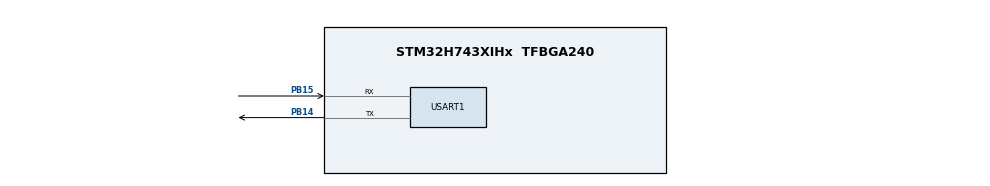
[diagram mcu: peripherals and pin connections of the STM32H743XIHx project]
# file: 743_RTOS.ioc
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FREERTOS.BinarySemaphores01=mySemaphore,Dynamic,NULL
FREERTOS.Events01=SendFlag,Dynamic,NULL
FREERTOS.Tasks01=defaultTask,24,128,StartDefaultTask,Default,NULL,Dynamic,NULL,NULL;myBuyTask,8,128,BuyTask,Default,(void *)mySemaphoreHandle,Dynamic,NULL,NULL;mySellTask,8,128,SellTask,Default,(void *)mySemaphoreHandle,Dynamic,NULL,NULL;mySendEvent,8,128,SendEvent,Default,NULL,Dynamic,NULL,NULL;myRcvEvent,8,128,RcvEvent,Default,NULL,Dynamic,NULL,NULL;myPoolTask01,8,128,PoolTask01,Default,(void *)properties,Dynamic,NULL,NULL;myPoolTask02,8,128,PoolTask02,Default,(void *)properties,Dynamic,NULL,NULL;myMailSendTask,8,128,MailSendTask,Default,NULL,Dynamic,NULL,NULL;myMailRcvTask,8,128,MailRcvTask,Default,NULL,Dynamic,NULL,NULL
Mcu.Family=STM32H7
Mcu.Name=STM32H743XIHx
Mcu.Package=TFBGA240
NVIC.PriorityGroup=NVIC_PRIORITYGROUP_4
NVIC.TIM7_IRQn=true\:15\:0\:false\:false\:true\:false\:false\:true\:true
NVIC.TimeBase=TIM7_IRQn
NVIC.TimeBaseIP=TIM7
NVIC.USART1_IRQn=true\:5\:0\:false\:false\:true\:true\:true\:true\:true
PB14.Mode=Asynchronous
PB14.Signal=USART1_TX
PB15.Mode=Asynchronous
PB15.Signal=USART1_RX
PH0-OSC_IN\ (PH0).Mode=HSE-External-Oscillator
PH0-OSC_IN\ (PH0).Signal=RCC_OSC_IN
PH1-OSC_OUT\ (PH1).Mode=HSE-External-Oscillator
PH1-OSC_OUT\ (PH1).Signal=RCC_OSC_OUT
ProjectManager.HeapSize=0x200
ProjectManager.StackSize=0x400
ProjectManager.TargetToolchain=EWARM V8.50
RCC.ADCFreq_Value=50390625
RCC.APB1Freq_Value=100000000
RCC.APB2Freq_Value=100000000
RCC.APB3Freq_Value=100000000
RCC.APB4Freq_Value=100000000
RCC.CortexFreq_Value=200000000
RCC.D1PPRE=RCC_APB3_DIV2
RCC.D2PPRE1=RCC_APB1_DIV2
RCC.D2PPRE2=RCC_APB2_DIV2
RCC.D3PPRE=RCC_APB4_DIV2
RCC.DIVM1=25
RCC.DIVN1=400
RCC.HCLKFreq_Value=200000000
RCC.PLLSourceVirtual=RCC_PLLSOURCE_HSE
RCC.PWR_Regulator_Voltage_Scale=PWR_REGULATOR_VOLTAGE_SCALE1
RCC.SYSCLKFreq_VALUE=200000000
RCC.SYSCLKSource=RCC_SYSCLKSOURCE_PLLCLK
RCC.USBFreq_Value=200000000
USART1.VirtualMode-Asynchronous=VM_ASYNC
VP_FREERTOS_VS_CMSIS_V2.Mode=CMSIS_V2
VP_SYS_VS_tim7.Mode=TIM7
board=custom

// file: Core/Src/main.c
/* USER CODE BEGIN Header */
/**
******************************************************************************
* @file           : main.c
* @brief          : Main program body
******************************************************************************
* @attention
*
* Copyright (c) 2023 STMicroelectronics.
* All rights reserved.
*
* This software is licensed under terms that can be found in the LICENSE file
* in the root directory of this software component.
* If no LICENSE file comes with this software, it is provided AS-IS.
*
******************************************************************************
*/
/* USER CODE END Header */
#include "main.h"
#include "cmsis_os.h"

/* USER CODE BEGIN Includes */
#include <stdio.h>
#include <string.h>
/* USER CODE END Includes */

/* USER CODE BEGIN PTD */
typedef struct {
    uint32_t len;
    uint32_t wid;
    uint32_t hei;
    uint32_t wei;
} properties_t;

typedef struct {
    double vol;
    double amp;
    double res;
} msg_t;
/* USER CODE END PTD */

UART_HandleTypeDef huart1;

/* Definitions for defaultTask */
osThreadId_t defaultTaskHandle;
const osThreadAttr_t defaultTask_attributes = {
    .name = "defaultTask",
    .stack_size = 128 * 4,
    .priority = (osPriority_t) osPriorityNormal,
};
/* Definitions for myBuyTask */
osThreadId_t myBuyTaskHandle;
const osThreadAttr_t myBuyTask_attributes = {
    .name = "myBuyTask",
    .stack_size = 128 * 4,
    .priority = (osPriority_t) osPriorityLow,
};
/* Definitions for mySellTask */
osThreadId_t mySellTaskHandle;
const osThreadAttr_t mySellTask_attributes = {
    .name = "mySellTask",
    .stack_size = 128 * 4,
    .priority = (osPriority_t) osPriorityLow,
};
/* Definitions for mySendEvent */
osThreadId_t mySendEventHandle;
const osThreadAttr_t mySendEvent_attributes = {
    .name = "mySendEvent",
    .stack_size = 128 * 4,
    .priority = (osPriority_t) osPriorityLow,
};
/* Definitions for myRcvEvent */
osThreadId_t myRcvEventHandle;
const osThreadAttr_t myRcvEvent_attributes = {
    .name = "myRcvEvent",
    .stack_size = 128 * 4,
    .priority = (osPriority_t) osPriorityLow,
};
/* Definitions for myPoolTask01 */
osThreadId_t myPoolTask01Handle;
const osThreadAttr_t myPoolTask01_attributes = {
    .name = "myPoolTask01",
    .stack_size = 128 * 4,
    .priority = (osPriority_t) osPriorityLow,
};
/* Definitions for myPoolTask02 */
osThreadId_t myPoolTask02Handle;
const osThreadAttr_t myPoolTask02_attributes = {
    .name = "myPoolTask02",
    .stack_size = 128 * 4,
    .priority = (osPriority_t) osPriorityLow,
};
/* Definitions for myMailSendTask */
osThreadId_t myMailSendTaskHandle;
const osThreadAttr_t myMailSendTask_attributes = {
    .name = "myMailSendTask",
    .stack_size = 128 * 4,
    .priority = (osPriority_t) osPriorityLow,
};
/* Definitions for myMailRcvTask */
osThreadId_t myMailRcvTaskHandle;
const osThreadAttr_t myMailRcvTask_attributes = {
    .name = "myMailRcvTask",
    .stack_size = 128 * 4,
    .priority = (osPriority_t) osPriorityLow,
};
/* Definitions for mySemaphore */
osSemaphoreId_t mySemaphoreHandle;
const osSemaphoreAttr_t mySemaphore_attributes = {
    .name = "mySemaphore"
};
/* Definitions for SendFlag */
osEventFlagsId_t SendFlagHandle;
const osEventFlagsAttr_t SendFlag_attributes = {
    .name = "SendFlag"
};
/* USER CODE BEGIN PV */
uint8_t g_iUartRx;
int g_iBuyFlag;
int g_iTicket;
int g_iSendFlag;

properties_t  *properties;
osMemoryPoolId_t poolHandle;

osMessageQueueId_t msgHandle;

/* USER CODE END PV */

void SystemClock_Config(void);
static void MX_GPIO_Init(void);
static void MX_USART1_UART_Init(void);
void StartDefaultTask(void *argument);
void BuyTask(void *argument);
void SellTask(void *argument);
void SendEvent(void *argument);
void RcvEvent(void *argument);
void PoolTask01(void *argument);
void PoolTask02(void *argument);
void MailSendTask(void *argument);
void MailRcvTask(void *argument);

int main(void)
{

    /* MCU Configuration--------------------------------------------------------*/

    /* Reset of all peripherals, Initializes the Flash interface and the Systick. */
    HAL_Init();

    /* Configure the system clock */
    SystemClock_Config();

    /* Initialize all configured peripherals */
    MX_GPIO_Init();
    MX_USART1_UART_Init();
    /* USER CODE BEGIN 2 */
    g_iBuyFlag = 0;
    g_iSendFlag = 0;
    g_iTicket = 100000;
    char buf[32];
    sprintf(buf, "USART Test\r\n");
    HAL_UART_Transmit(&huart1, (uint8_t*)buf, strlen(buf), 100);
    HAL_UART_Receive_IT(&huart1, &g_iUartRx, sizeof(g_iUartRx));

    poolHandle = osMemoryPoolNew(16, sizeof(properties_t), NULL);

    /* USER CODE END 2 */

    /* Init scheduler */
    osKernelInitialize();

    /* Create the semaphores(s) */
    /* creation of mySemaphore */
    mySemaphoreHandle = osSemaphoreNew(1, 1, &mySemaphore_attributes);

    /* USER CODE BEGIN RTOS_QUEUES */
    /* add queues, ... */
    msgHandle = osMessageQueueNew(16, sizeof(msg_t), NULL);
    /* USER CODE END RTOS_QUEUES */

    /* Create the thread(s) */
    /* creation of defaultTask */
    defaultTaskHandle = osThreadNew(StartDefaultTask, NULL, &defaultTask_attributes);

    /* creation of myBuyTask */
    myBuyTaskHandle = osThreadNew(BuyTask, (void *)mySemaphoreHandle, &myBuyTask_attributes);

    /* creation of mySellTask */
    mySellTaskHandle = osThreadNew(SellTask, (void *)mySemaphoreHandle, &mySellTask_attributes);

    /* creation of mySendEvent */
    mySendEventHandle = osThreadNew(SendEvent, NULL, &mySendEvent_attributes);

    /* creation of myRcvEvent */
    myRcvEventHandle = osThreadNew(RcvEvent, NULL, &myRcvEvent_attributes);

    /* creation of myPoolTask01 */
    myPoolTask01Handle = osThreadNew(PoolTask01, (void *)properties, &myPoolTask01_attributes);

    /* creation of myPoolTask02 */
    myPoolTask02Handle = osThreadNew(PoolTask02, (void *)properties, &myPoolTask02_attributes);

    /* creation of myMailSendTask */
    myMailSendTaskHandle = osThreadNew(MailSendTask, NULL, &myMailSendTask_attributes);

    /* creation of myMailRcvTask */
    myMailRcvTaskHandle = osThreadNew(MailRcvTask, NULL, &myMailRcvTask_attributes);

    /* Create the event(s) */
    /* creation of SendFlag */
    SendFlagHandle = osEventFlagsNew(&SendFlag_attributes);

    /* Start scheduler */
    osKernelStart();
    /* We should never get here as control is now taken by the scheduler */
    /* Infinite loop */
    while (1)
    {

    }
}

void SystemClock_Config(void)
{
    RCC_OscInitTypeDef RCC_OscInitStruct = {0};
    RCC_ClkInitTypeDef RCC_ClkInitStruct = {0};

    /** Supply configuration update enable
    */
    HAL_PWREx_ConfigSupply(PWR_LDO_SUPPLY);

    /** Configure the main internal regulator output voltage
    */
    __HAL_PWR_VOLTAGESCALING_CONFIG(PWR_REGULATOR_VOLTAGE_SCALE1);

    while(!__HAL_PWR_GET_FLAG(PWR_FLAG_VOSRDY)) {}

    /** Initializes the RCC Oscillators according to the specified parameters
    * in the RCC_OscInitTypeDef structure.
    */
    RCC_OscInitStruct.OscillatorType = RCC_OSCILLATORTYPE_HSE;
    RCC_OscInitStruct.HSEState = RCC_HSE_ON;
    RCC_OscInitStruct.PLL.PLLState = RCC_PLL_ON;
    RCC_OscInitStruct.PLL.PLLSource = RCC_PLLSOURCE_HSE;
    RCC_OscInitStruct.PLL.PLLM = 25;
    RCC_OscInitStruct.PLL.PLLN = 400;
    RCC_OscInitStruct.PLL.PLLP = 2;
    RCC_OscInitStruct.PLL.PLLQ = 2;
    RCC_OscInitStruct.PLL.PLLR = 2;
    RCC_OscInitStruct.PLL.PLLRGE = RCC_PLL1VCIRANGE_0;
    RCC_OscInitStruct.PLL.PLLVCOSEL = RCC_PLL1VCOWIDE;
    RCC_OscInitStruct.PLL.PLLFRACN = 0;
    if (HAL_RCC_OscConfig(&RCC_OscInitStruct) != HAL_OK)
    {
        Error_Handler();
    }

    /** Initializes the CPU, AHB and APB buses clocks
    */
    RCC_ClkInitStruct.ClockType = RCC_CLOCKTYPE_HCLK|RCC_CLOCKTYPE_SYSCLK
        |RCC_CLOCKTYPE_PCLK1|RCC_CLOCKTYPE_PCLK2
            |RCC_CLOCKTYPE_D3PCLK1|RCC_CLOCKTYPE_D1PCLK1;
    RCC_ClkInitStruct.SYSCLKSource = RCC_SYSCLKSOURCE_PLLCLK;
    RCC_ClkInitStruct.SYSCLKDivider = RCC_SYSCLK_DIV1;
    RCC_ClkInitStruct.AHBCLKDivider = RCC_HCLK_DIV1;
    RCC_ClkInitStruct.APB3CLKDivider = RCC_APB3_DIV2;
    RCC_ClkInitStruct.APB1CLKDivider = RCC_APB1_DIV2;
    RCC_ClkInitStruct.APB2CLKDivider = RCC_APB2_DIV2;
    RCC_ClkInitStruct.APB4CLKDivider = RCC_APB4_DIV2;

    if (HAL_RCC_ClockConfig(&RCC_ClkInitStruct, FLASH_LATENCY_2) != HAL_OK)
    {
        Error_Handler();
    }
}

static void MX_USART1_UART_Init(void)
{

    huart1.Instance = USART1;
    huart1.Init.BaudRate = 115200;
    huart1.Init.WordLength = UART_WORDLENGTH_8B;
    huart1.Init.StopBits = UART_STOPBITS_1;
    huart1.Init.Parity = UART_PARITY_NONE;
    huart1.Init.Mode = UART_MODE_TX_RX;
    huart1.Init.HwFlowCtl = UART_HWCONTROL_NONE;
    huart1.Init.OverSampling = UART_OVERSAMPLING_16;
    huart1.Init.OneBitSampling = UART_ONE_BIT_SAMPLE_DISABLE;
    huart1.Init.ClockPrescaler = UART_PRESCALER_DIV1;
    huart1.AdvancedInit.AdvFeatureInit = UART_ADVFEATURE_NO_INIT;
    if (HAL_UART_Init(&huart1) != HAL_OK)
    {
        Error_Handler();
    }
    if (HAL_UARTEx_SetTxFifoThreshold(&huart1, UART_TXFIFO_THRESHOLD_1_8) != HAL_OK)
    {
        Error_Handler();
    }
    if (HAL_UARTEx_SetRxFifoThreshold(&huart1, UART_RXFIFO_THRESHOLD_1_8) != HAL_OK)
    {
        Error_Handler();
    }
    if (HAL_UARTEx_DisableFifoMode(&huart1) != HAL_OK)
    {
        Error_Handler();
    }

}

static void MX_GPIO_Init(void)
{

    /* GPIO Ports Clock Enable */
    __HAL_RCC_GPIOH_CLK_ENABLE();
    __HAL_RCC_GPIOB_CLK_ENABLE();

}

/* USER CODE BEGIN 4 */
void HAL_UART_RxCpltCallback(UART_HandleTypeDef *huart)
{
    g_iBuyFlag = 1;
    if(g_iUartRx == '1')
    {
        g_iSendFlag = 1;
    }
    HAL_UART_Receive_IT(&huart1, &g_iUartRx, sizeof(g_iUartRx));
}
/* USER CODE END 4 */

void StartDefaultTask(void *argument)
{
    for(;;)
    {
        osDelay(1);
    }
}

void BuyTask(void *argument)
{
    /* USER CODE BEGIN BuyTask */
    osSemaphoreId semaphore = (osSemaphoreId)argument;
    /* Infinite loop */
    for(;;)
    {
        if(g_iBuyFlag == 1)
        {
            if(semaphore != NULL)
            {
                if(osSemaphoreAcquire(semaphore, 0) == osOK)
                {
                    g_iTicket--;
                    g_iBuyFlag = 0;
                }
                osSemaphoreRelease(semaphore);
            }
        }

        osDelay(100);
    }
    /* USER CODE END BuyTask */
}

void SellTask(void *argument)
{
    /* USER CODE BEGIN SellTask */
    osSemaphoreId semaphore = (osSemaphoreId)argument;
    char buf[16];

    /* Infinite loop */
    for(;;)
    {
        if(semaphore != NULL)
        {
            if(osSemaphoreAcquire(semaphore, 0) == osOK)
            {
                sprintf(buf, "%d\r\n", g_iTicket);
                HAL_UART_Transmit(&huart1, (uint8_t*)buf, strlen(buf), 10);
            }
            osSemaphoreRelease(semaphore);
        }
        osDelay(500);
    }
    /* USER CODE END SellTask */
}

void SendEvent(void *argument)
{
    /* USER CODE BEGIN SendEvent */

    /* Infinite loop */
    for(;;)
    {
        if(g_iSendFlag == 1)
        {
            osEventFlagsSet(SendFlagHandle, 1);
            g_iSendFlag = 0;
        }
        osDelay(100);
    }
    /* USER CODE END SendEvent */
}

void RcvEvent(void *argument)
{
    /* USER CODE BEGIN RcvEvent */
    uint32_t flags;
    char buf[32];

    /* Infinite loop */
    for(;;)
    {
        //        flags = osEventFlagsWait(SendFlagHandle, 1, osFlagsWaitAny, osWaitForever);
        flags = osEventFlagsWait(SendFlagHandle, 1, osFlagsWaitAny, 1000);
        if(flags == 1)
        {
            sprintf(buf, "Rcv Cplt\r\n");
            HAL_UART_Transmit(&huart1, (uint8_t*)buf, strlen(buf), 100);
        }
        else
        {
            sprintf(buf, "TimeOut\r\n");
            HAL_UART_Transmit(&huart1, (uint8_t*)buf, strlen(buf), 100);
        }
        osDelay(100);
    }
    /* USER CODE END RcvEvent */
}

void PoolTask01(void *argument)
{
    /* USER CODE BEGIN PoolTask01 */
    properties_t *arg_properties = (properties_t *)argument;
    arg_properties[0].hei = 0;
    arg_properties[0].len = 10;
    arg_properties[0].wei = 100;
    arg_properties[0].wid = 1000;
    char buf[64];

    /* Infinite loop */
    for(;;)
    {
        arg_properties[0].hei++;
        arg_properties[0].len++;
        arg_properties[0].wei++;
        arg_properties[0].wid++;

        sprintf(buf, "PoolTask01 : (%d, %d, %d, %d)\r\n", arg_properties[0].hei, arg_properties[0].len, arg_properties[0].wei, arg_properties[0].wid);
        HAL_UART_Transmit(&huart1, (uint8_t *)buf, strlen(buf), 100);

        osDelay(500);
    }
    /* USER CODE END PoolTask01 */
}

void PoolTask02(void *argument)
{
    /* USER CODE BEGIN PoolTask02 */
    properties_t *arg_properties = (properties_t *)argument;
    char buf[64];
    /* Infinite loop */
    for(;;)
    {
        arg_properties[0].hei++;
        arg_properties[0].len++;
        arg_properties[0].wei++;
        arg_properties[0].wid++;

        sprintf(buf, "PoolTask02 : (%d, %d, %d, %d)\r\n", arg_properties[0].hei, arg_properties[0].len, arg_properties[0].wei, arg_properties[0].wid);
        HAL_UART_Transmit(&huart1, (uint8_t *)buf, strlen(buf), 100);

        osDelay(800);
    }
    /* USER CODE END PoolTask02 */
}

void MailSendTask(void *argument)
{
    /* USER CODE BEGIN MailSendTask */
    msg_t msg;
    msg.vol = 0.0;
    msg.amp = 0.0;
    msg.res = 0.0;
    int i = 30;
    /* Infinite loop */
    for(;;)
    {
        msg.vol = 3.3 * i;
        msg.amp = 20.0;
        msg.res = msg.vol / msg.amp;
        osMessageQueuePut(msgHandle, &msg, 0, 0);
        osDelay(300);
        i++;
    }
    /* USER CODE END MailSendTask */
}

void MailRcvTask(void *argument)
{
    /* USER CODE BEGIN MailRcvTask */
    msg_t msg;
    osStatus_t status;
    char buf[48];
    /* Infinite loop */
    for(;;)
    {
        status = osMessageQueueGet(msgHandle, &msg, 0, 0);
        if(status == osOK)
        {
            sprintf(buf, "Vol : %.1f, Amp : %.1f, Res : %.1f\r\n", msg.vol, msg.amp, msg.res);
            HAL_UART_Transmit(&huart1, (uint8_t *)buf, strlen(buf), 100);
        }
        osDelay(1);
    }
    /* USER CODE END MailRcvTask */
}

void HAL_TIM_PeriodElapsedCallback(TIM_HandleTypeDef *htim)
{
    if (htim->Instance == TIM7) {
        HAL_IncTick();
    }
}

void Error_Handler(void)
{
    __disable_irq();
    while (1)
    {
    }
}
